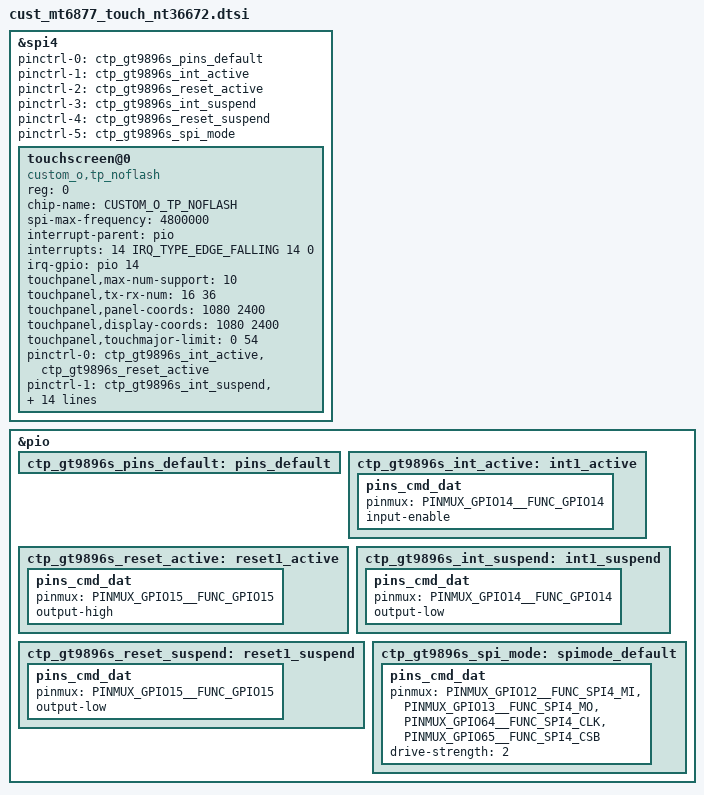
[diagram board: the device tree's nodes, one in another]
/*
 * Copyright (c) 2019 MediaTek Inc.
 *
 * This program is free software; you can redistribute it and/or modify
 * it under the terms of the GNU General Public License version 2 as
 * published by the Free Software Foundation.
 *
 * This program is distributed in the hope that it will be useful,
 * but WITHOUT ANY WARRANTY; without even the implied warranty of
 * MERCHANTABILITY or FITNESS FOR A PARTICULAR PURPOSE.  See the
 * GNU General Public License for more details.
 */
/* TOUCH start */
&spi4 {
	status = "okay";
	#address-cells = <1>;
	#size-cells = <0>;
	pinctrl-names = "default", "gt9896s_int_active",
		"gt9896s_reset_active", "gt9896s_int_suspend",
		"gt9896s_reset_suspend", "gt9896s_spi_mode";
	pinctrl-0 = <&ctp_gt9896s_pins_default>;
	pinctrl-1 = <&ctp_gt9896s_int_active>;
	pinctrl-2 = <&ctp_gt9896s_reset_active>;
	pinctrl-3 = <&ctp_gt9896s_int_suspend>;
	pinctrl-4 = <&ctp_gt9896s_reset_suspend>;
	pinctrl-5 = <&ctp_gt9896s_spi_mode>;

	touchscreen@0 {
		compatible = "custom_o,tp_noflash";
		reg = <0>;
		chip-name = "CUSTOM_O_TP_NOFLASH";
		status = "ok";
		//4800000,9600000,15000000,19200000
		spi-max-frequency = <4800000>;
		interrupt-parent = <&pio>;
		interrupts = <14 IRQ_TYPE_EDGE_FALLING 14 0>;
		irq-gpio = <&pio 14 0x2002>;
		//reset-gpio = <&pio 20 0>;
		//lcd-reset-gpio = <&pio 20 0>;

		touchpanel,max-num-support = <10>;
		touchpanel,tx-rx-num = <16 36>;
		touchpanel,panel-coords = <1080 2400>;
		touchpanel,display-coords = <1080 2400>;
		touchpanel,touchmajor-limit = <0 54>;

		pinctrl-names = "default", "suspend";
		pinctrl-0 = <&ctp_gt9896s_int_active
				&ctp_gt9896s_reset_active>;
		pinctrl-1 = <&ctp_gt9896s_int_suspend
				&ctp_gt9896s_reset_suspend>;

		incell_screen;
		fw_edge_limit_support;
		black_gesture_support;
		charger_pump_support;
		headset_pump_support;
		esd_handle_support;
		black_gesture_test_support;
		game_switch_support;
		noflash_support;
		//lcd_trigger_load_tp_fw_support;
		smart_gesture_support;
		pressure_report_support;
		//fw_update_app_support;
		fw_update_in_probe_with_headfile;

		touchpanel,button-type = <4>;
	};
};

&pio {
	ctp_gt9896s_pins_default: pins_default {
	};
	ctp_gt9896s_int_active: int1_active {
		pins_cmd_dat {
			pinmux = <PINMUX_GPIO14__FUNC_GPIO14>;
			input-enable;
		};
	};
	ctp_gt9896s_reset_active: reset1_active {
		pins_cmd_dat {
			pinmux = <PINMUX_GPIO15__FUNC_GPIO15>;
			output-high;
		};
	};
	ctp_gt9896s_int_suspend: int1_suspend {
		pins_cmd_dat {
			pinmux = <PINMUX_GPIO14__FUNC_GPIO14>;
			output-low;
		};
	};
	ctp_gt9896s_reset_suspend: reset1_suspend {
		pins_cmd_dat {
			pinmux = <PINMUX_GPIO15__FUNC_GPIO15>;
			output-low;
		};
	};
	ctp_gt9896s_spi_mode: spimode_default {
		pins_cmd_dat {
			pinmux = <PINMUX_GPIO12__FUNC_SPI4_MI>,
				<PINMUX_GPIO13__FUNC_SPI4_MO>,
				<PINMUX_GPIO64__FUNC_SPI4_CLK>,
				<PINMUX_GPIO65__FUNC_SPI4_CSB>;
			drive-strength = <2>;
		};
	};
};
/* TOUCH end */
